AUTOSAR XML (schema 4-0-3)
standard types defined: Boolean, UInt8
package /AUTOSAR_Platform/DataConstrs
  range DC_Boolean: raw 0..1
  range DC_UInt8: raw 0..255
package /PATAC/EEPROM/BaseData
  base type PJB_EEP_Uint8: category=FIXED_LENGTH, base-type-size=8, base-type-encoding=NONE, native-declaration=unsigned char
package /PATAC/EEPROM/ImplementationDataType
  impl type EEP_Uint8: category=VALUE, base-type=PJB_EEP_Uint8, sw-calibration-access=READ-ONLY, type-emitter=RTE
package /PATAC/MSM/ComponentTypes
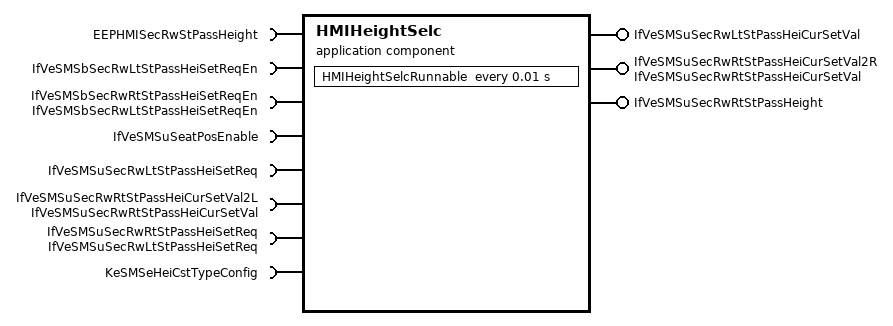
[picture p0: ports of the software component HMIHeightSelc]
  application sw component type HMIHeightSelc
    provide port IfVeSMSuSecRwLtStPassHeiCurSetVal: nonqueued-sender-com-spec{data-element=IfVeSMSuSecRwLtStPassHeiCurSetVal/Val, init-value=0}, provided-interface=IfVeSMSuSecRwLtStPassHeiCurSetVal
    provide port IfVeSMSuSecRwRtStPassHeiCurSetVal2R: nonqueued-sender-com-spec{data-element=IfVeSMSuSecRwRtStPassHeiCurSetVal/Val, init-value=0}, provided-interface=IfVeSMSuSecRwRtStPassHeiCurSetVal
    provide port IfVeSMSuSecRwRtStPassHeight: nonqueued-sender-com-spec{data-element=IfVeSMSuSecRwRtStPassHeight/Val, init-value=0}, provided-interface=IfVeSMSuSecRwRtStPassHeight
    8 x require port:
      EEPHMISecRwStPassHeight: required-com-specs=[Get, Set], required-interface=EEPHMISecRwStPassHeight
      IfVeSMSbSecRwLtStPassHeiSetReqEn: nonqueued-receiver-com-spec{data-element=IfVeSMSbSecRwLtStPassHeiSetReqEn/Val, filter=data-filter-type=ALWAYS, init-value=0}, required-interface=IfVeSMSbSecRwLtStPassHeiSetReqEn
      IfVeSMSbSecRwRtStPassHeiSetReqEn: nonqueued-receiver-com-spec{data-element=IfVeSMSbSecRwLtStPassHeiSetReqEn/Val, filter=data-filter-type=ALWAYS, init-value=0}, required-interface=IfVeSMSbSecRwLtStPassHeiSetReqEn
      IfVeSMSuSeatPosEnable: nonqueued-receiver-com-spec{data-element=IfVeSMSuSeatPosEnable/Val, filter=data-filter-type=ALWAYS, init-value=0}, required-interface=IfVeSMSuSeatPosEnable
      IfVeSMSuSecRwLtStPassHeiSetReq: nonqueued-receiver-com-spec{data-element=IfVeSMSuSecRwLtStPassHeiSetReq/Val, filter=data-filter-type=ALWAYS, init-value=0}, required-interface=IfVeSMSuSecRwLtStPassHeiSetReq
      IfVeSMSuSecRwRtStPassHeiCurSetVal2L: nonqueued-receiver-com-spec{data-element=IfVeSMSuSecRwRtStPassHeiCurSetVal/Val, filter=data-filter-type=ALWAYS, init-value=0}, required-interface=IfVeSMSuSecRwRtStPassHeiCurSetVal
      IfVeSMSuSecRwRtStPassHeiSetReq: nonqueued-receiver-com-spec{data-element=IfVeSMSuSecRwLtStPassHeiSetReq/Val, filter=data-filter-type=ALWAYS, init-value=0}, required-interface=IfVeSMSuSecRwLtStPassHeiSetReq
      KeSMSeHeiCstTypeConfig: parameter-require-com-spec{init-value=0, parameter=Val}, required-interface=KeSMSeHeiCstTypeConfig
    behavior HMIHeightSelc_InternalBehavior
      timing event TMT_HMIHeightSelcRunnable: start-on-event=HMIHeightSelcRunnable, period=0.01
      runnable HMIHeightSelcRunnable
        data-receive-point-by-arguments:
          6 x access:
            REC_IfVeSMSbSecRwLtStPassHeiSetReqEn_Val: accessed-variable=IfVeSMSbSecRwLtStPassHeiSetReqEn.Val
            REC_IfVeSMSbSecRwRtStPassHeiSetReqEn_Val: accessed-variable=IfVeSMSbSecRwRtStPassHeiSetReqEn.Val
            REC_IfVeSMSuSeatPosEnable_Val: accessed-variable=IfVeSMSuSeatPosEnable.Val
            REC_IfVeSMSuSecRwLtStPassHeiSetReq_Val: accessed-variable=IfVeSMSuSecRwLtStPassHeiSetReq.Val
            REC_IfVeSMSuSecRwRtStPassHeiSetReq_Val: accessed-variable=IfVeSMSuSecRwRtStPassHeiSetReq.Val
            SEND_IfVeSMSuSecRwRtStPassHeiCurSetVal_Val: accessed-variable=IfVeSMSuSecRwRtStPassHeiCurSetVal2L.Val
        data-send-points:
          access SEND_IfVeSMSuSecRwLtStPassHeiCurSetVal_Val: accessed-variable=IfVeSMSuSecRwLtStPassHeiCurSetVal.Val
          access SEND_IfVeSMSuSecRwRtStPassHeiCurSetVal2R_Val: accessed-variable=IfVeSMSuSecRwRtStPassHeiCurSetVal2R.Val
          access SEND_IfVeSMSuSecRwRtStPassHeight_Val: accessed-variable=IfVeSMSuSecRwRtStPassHeight.Val
        parameter access PA_KeSMSeHeiCstTypeConfig_Val: accessed-parameter=KeSMSeHeiCstTypeConfig.Val
        sync call SC_EEPHMISecRwStPassHeight_Get: operation=EEPHMISecRwStPassHeight.Get, timeout=0
        sync call SC_EEPHMISecRwStPassHeight_Set: operation=EEPHMISecRwStPassHeight.Set, timeout=0
  swc implementation HMIHeightSelc_Implementation: behavior=HMIHeightSelc_InternalBehavior
    code-descriptors:
      code Default: artifact-descriptors=autosar-engineering-object={short-label=Default, category=SWSRC}
package /PATAC/MSM/ModeAdjust/CalPortInterface
  parameter interface KeSMSeHeiCstTypeConfig
    parameter data prototype Val: sw-calibration-access=READ-WRITE, type=UInt8
package /PATAC/MSM/ModeAdjust/PortInterface
  client server interface EEPHMISecRwStPassHeight
    operation Get
      arg arg: type=EEP_Uint8, direction=OUT, server-argument-impl-policy=USE-ARGUMENT-TYPE
    operation Set
      arg arg: type=EEP_Uint8, direction=IN, server-argument-impl-policy=USE-ARGUMENT-TYPE
  5 x sender receiver interface:
    IfVeSMSbSecRwLtStPassHeiSetReqEn: invalidation-policy{data-element=IfVeSMSbSecRwLtStPassHeiSetReqEn/Val, handle-invalid=DONT-INVALIDATE}
      data Val: type=Boolean
    IfVeSMSuSecRwLtStPassHeiCurSetVal: invalidation-policy{data-element=IfVeSMSuSecRwLtStPassHeiCurSetVal/Val, handle-invalid=DONT-INVALIDATE}
      data Val: type=UInt8
    IfVeSMSuSecRwLtStPassHeiSetReq: invalidation-policy{data-element=IfVeSMSuSecRwLtStPassHeiSetReq/Val, handle-invalid=DONT-INVALIDATE}
      data Val: type=UInt8
    IfVeSMSuSecRwRtStPassHeiCurSetVal: invalidation-policy{data-element=IfVeSMSuSecRwRtStPassHeiCurSetVal/Val, handle-invalid=DONT-INVALIDATE}
      data Val: type=UInt8
    IfVeSMSuSecRwRtStPassHeight: invalidation-policy{data-element=IfVeSMSuSecRwRtStPassHeight/Val, handle-invalid=DONT-INVALIDATE}
      data Val: type=UInt8
package /PATAC/MSM/PortInterfaces
  sender receiver interface IfVeSMSuSeatPosEnable: invalidation-policy{data-element=IfVeSMSuSeatPosEnable/Val, handle-invalid=DONT-INVALIDATE}
    data Val: type=UInt8
